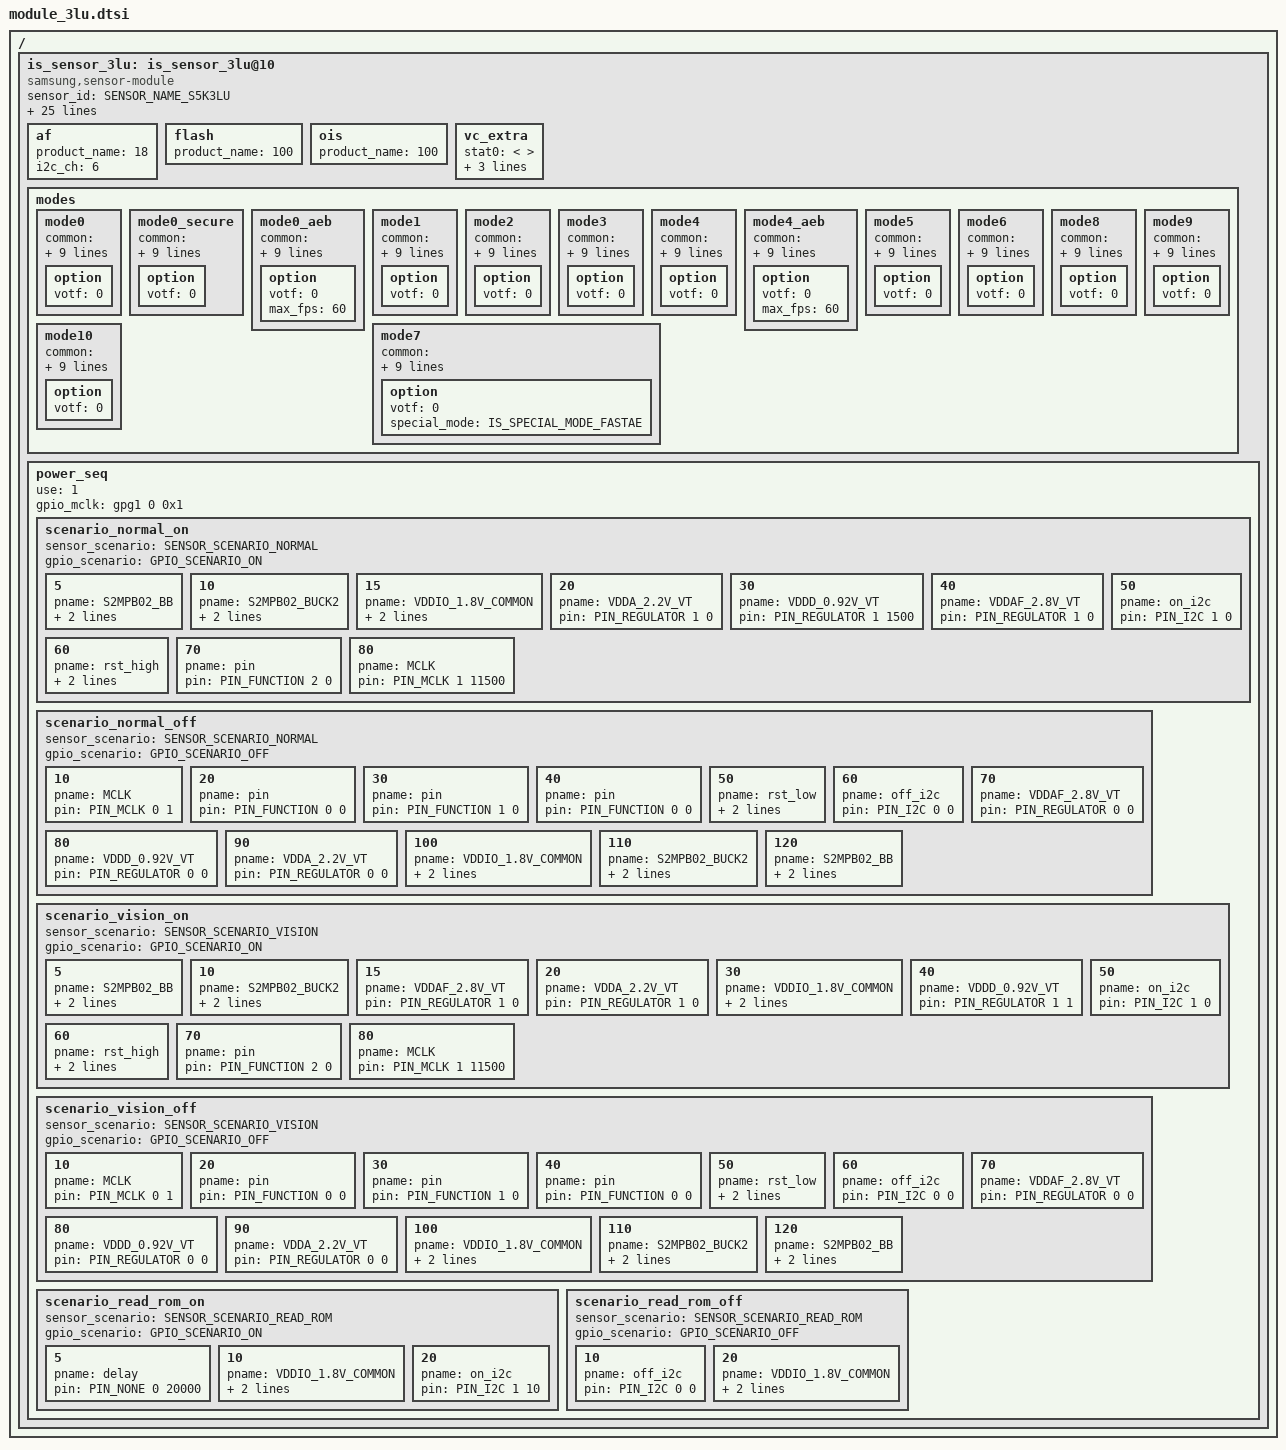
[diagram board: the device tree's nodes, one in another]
/*
 * SAMSUNG EXYNOSxxxx board camera device tree source
 *
 * Copyright (c) 2019 Samsung Electronics Co., Ltd.
 *		http://www.samsung.com
 *
 * This program is free software; you can redistribute it and/or modify
 * it under the terms of the GNU General Public License version 2 as
 * published by the Free Software Foundation.
 */

#include <dt-bindings/camera/exynos_is_dt.h>

/ {
	fragment@camera {
		target-path = "/";
		__overlay__ {
			is_sensor_3lu: is_sensor_3lu@10 {
				compatible = "samsung,sensor-module";

				/* common */
				sensor_id = <SENSOR_NAME_S5K3LU>;
				active_width = <4000>;
				active_height = <3000>;
				margin_left = <0>;
				margin_right = <0>;
				margin_top = <0>;
				margin_bottom = <0>;
				max_framerate = <240>;
				bitwidth = <10>;
				use_retention_mode = <SENSOR_RETENTION_UNSUPPORTED>;
				sensor_maker = "SLSI";
				sensor_name = "S5K3LU";
				setfile_name = "setfile_3lu.bin";

				status = "okay";

				/* board */
				pinctrl-names = "pin0", "pin1", "pin2", "release";
				pinctrl-0 = <>;
				pinctrl-1 = <&sensor_mclk0_out>;
				pinctrl-2 = <&sensor_mclk0_fn>;
				pinctrl-3 = <>;

				position = <1>;	/* Rear:0. Front:1. Rear_sub:2. Secure:3. */
				id = <1>; /* is_sensor id */
				mclk_ch = <0>;
				mclk_freq = <19200>;
				sensor_i2c_ch = <5>; /* SENSOR_CONTROL_I2C5 */

				/* vendor */
				rom_type = <2>; /* ROM_TYPE_EEPROM */
				rom_id = <1>;
				rom_cal_index = <0>;

				/* peri*/
				af {
					product_name = <18>; /* ACTUATOR_NAME_AK737X */
					i2c_ch = <6>; /* SENSOR_CONTROL_I2C6 */
				};

				flash {
					product_name = <100>; /* NOTHING */
				};

				ois {
					product_name = <100>; /* NOTHING */
				};

				vc_extra {
					/* ex) statX = <stat_type, sensor_mode, max_width, max_height, max_element> */
					stat0 = </* not available */>;									/* VC_BUF_DATA_TYPE_SENSOR_STAT1 */
					stat1 = </*VC_STAT_TYPE_PDP_4_1_PDAF_STAT0*/ 1200 /*VC_SENSOR_MODE_2PD_MODE3*/ 102 4000 750 2>;	/* VC_BUF_DATA_TYPE_GENERAL_STAT1 */
					stat2 = </* not available */>;									/* VC_BUF_DATA_TYPE_SENSOR_STAT2 */
					stat3 = </*VC_STAT_TYPE_PDP_4_1_PDAF_STAT1*/ 1201 /*VC_SENSOR_MODE_2PD_MODE3*/ 102 4000 750 2>;	/* VC_BUF_DATA_TYPE_GENERAL_STAT2 */
				};

				/* sensor modes */
				/*
					SENSOR_3LU_4000X3000_60FPS_10BIT = 0, // A-01-A
					SENSOR_3LU_3392X2544_60FPS_10BIT = 1, // A-01-B
					SENSOR_3LU_3392X1908_60FPS_10BIT = 2, // A-01-C
					SENSOR_3LU_4000X3000_30FPS_ADC = 3, // A-04
					SENSOR_3LU_4000X2252_60FPS_10BIT = 4, // A-09-B
					SENSOR_3LU_4000X2252_60FPS_ADC = 5, // A-12
					SENSOR_3LU_2000X1124_120FPS_10BIT = 6, // B-01
					SENSOR_3LU_2000X1500_120FPS_FAST_AE = 7, // C-02
					SENSOR_3LU_2000X1500_30FPS_10BIT = 8, // C-04-A
					SENSOR_3LU_1696X1272_30FPS_10BIT = 9, // C-04-B
					SENSOR_3LU_1696X954_30FPS_10BIT = 10, // C-04-C
					SENSOR_3LU_4000X3000_30FPS_DSG, // A-03
					SENSOR_3LU_4000X3000_30FPS_12BIT_LN2, // A-06
					SENSOR_3LU_4000X3000_60FPS_AEB, // A-05
					SENSOR_3LU_4000X3000_15FPS_10BIT_LN4, // A-07
					SENSOR_3LU_4000X2252_30FPS_DSG, // A-11-A
					SENSOR_3LU_4000X2252_30FPS_12BIT_LN2, // A-14-A
					SENSOR_3LU_4000X2252_15FPS_10BIT_LN4, // A-16
					SENSOR_3LU_4000X2252_30FPS_10BIT_LN2, // A-18
					SENSOR_3LU_4000X2252_60FPS_AEB, // A-19
				*/
				modes {
					/* common = <width, height, fps, settle, mode, lane, speed, interleave, lrte, pd_mode> */
					/* vcX = <map, hwformat, width, height, hwformat, type, width, height> */
					mode0 { /* SENSOR_3LU_4000X3000_60FPS_10BIT = 0 */ /* A-01-A */
						common = <4000 3000 60 0 0 CSI_DATA_LANES_3 1862 CSI_MODE_VC_DT LRTE_ENABLE PD_MOD3>;
						vc0 = </* in */ 0 HW_FORMAT_RAW10 DATA_IMG 4000 3000	/* out */ HW_FORMAT_RAW10 VC_NOTHING 4000 3000>;
						vc1 = </* in */ 2 HW_FORMAT_UNKNOWN DATA_NONE 0 0		/* out */ HW_FORMAT_UNKNOWN VC_NOTHING 0 0>;
						vc2 = </* in */ 1 HW_FORMAT_RAW10_POTF DATA_HPD 4000 750	/* out */ HW_FORMAT_RAW10_POTF VC_TAILPDAF 4000 750>;
						vc3 = </* in */ 3 HW_FORMAT_UNKNOWN DATA_NONE 0 0		/* out */ HW_FORMAT_UNKNOWN VC_NOTHING 0 0>;
						option { votf = <0>; };
					};
					mode0_secure { /* A-17 */
						common = <4000 3000 60 0 0 CSI_DATA_LANES_3 1862 CSI_MODE_VC_DT LRTE_ENABLE PD_NONE EX_PDSTAT_OFF>;
						vc0 = </* in */ 0 HW_FORMAT_RAW10 DATA_IMG 4000 3000	/* out */ HW_FORMAT_RAW10 VC_NOTHING 2000 1500>;
						vc1 = </* in */ 2 HW_FORMAT_UNKNOWN DATA_NONE 0 0		/* out */ HW_FORMAT_UNKNOWN VC_NOTHING 0 0>;
						vc2 = </* in */ 1 HW_FORMAT_RAW10_POTF DATA_HPD 4000 750	/* out */ HW_FORMAT_RAW10 VC_NOTHING 0 0>;
						vc3 = </* in */ 3 HW_FORMAT_UNKNOWN DATA_NONE 0 0		/* out */ HW_FORMAT_UNKNOWN VC_NOTHING 0 0>;
						option { votf = <0>; };
					};
					mode0_aeb { /* SENSOR_3LU_4000X3000_60FPS_10BIT = 0 */ /* A-01-A */ /* AEB */
						common = <4000 3000 60 0 0 CSI_DATA_LANES_3 1862 CSI_MODE_VC_DT LRTE_ENABLE PD_MOD3 EX_AEB>;
						vc0 = </* in */ 0 HW_FORMAT_RAW10 DATA_IMG 4000 3000	/* out */ HW_FORMAT_RAW10 VC_NOTHING 4000 3000>;
						vc1 = </* in */ 2 HW_FORMAT_RAW10 DATA_IMG 4000 3000	/* out */ HW_FORMAT_RAW10 VC_NOTHING 4000 3000>;
						vc2 = </* in */ 1 HW_FORMAT_RAW10_POTF DATA_HPD 4000 750	/* out */ HW_FORMAT_RAW10_POTF VC_TAILPDAF 4000 750>;
						vc3 = </* in */ 3 HW_FORMAT_RAW10_POTF DATA_HPD 4000 750	/* out */ HW_FORMAT_UNKNOWN VC_NOTHING 0 0>;
						option { votf = <0>; max_fps = <60>; };
					};
					mode1 { /* SENSOR_3LU_3392X2544_60FPS_10BIT = 1 */ /* A-01-B */
						common = <3392 2544 60 0 1 CSI_DATA_LANES_3 1862 CSI_MODE_VC_DT LRTE_ENABLE PD_MOD3>;
						vc0 = </* in */ 0 HW_FORMAT_RAW10 DATA_IMG 3392 2544	/* out */ HW_FORMAT_RAW10 VC_NOTHING 3392 2544>;
						vc1 = </* in */ 2 HW_FORMAT_UNKNOWN DATA_NONE 0 0		/* out */ HW_FORMAT_UNKNOWN VC_NOTHING 0 0>;
						vc2 = </* in */ 1 HW_FORMAT_RAW10_POTF DATA_HPD 3392 636	/* out */ HW_FORMAT_RAW10_POTF VC_TAILPDAF 3392 636>;
						vc3 = </* in */ 3 HW_FORMAT_UNKNOWN DATA_NONE 0 0		/* out */ HW_FORMAT_UNKNOWN VC_NOTHING 0 0>;
						option { votf = <0>; };
					};
					mode2 { /* SENSOR_3LU_3392X1908_60FPS_10BIT = 2 */ /* A-01-C */
						common = <3392 1908 60 0 2 CSI_DATA_LANES_3 1862 CSI_MODE_VC_DT LRTE_ENABLE PD_MOD3>;
						vc0 = </* in */ 0 HW_FORMAT_RAW10 DATA_IMG 3392 1908	/* out */ HW_FORMAT_RAW10 VC_NOTHING 3392 1908>;
						vc1 = </* in */ 2 HW_FORMAT_UNKNOWN DATA_NONE 0 0		/* out */ HW_FORMAT_UNKNOWN VC_NOTHING 0 0>;
						vc2 = </* in */ 1 HW_FORMAT_RAW10_POTF DATA_HPD 3392 476	/* out */ HW_FORMAT_RAW10_POTF VC_TAILPDAF 3392 476>;
						vc3 = </* in */ 3 HW_FORMAT_UNKNOWN DATA_NONE 0 0		/* out */ HW_FORMAT_UNKNOWN VC_NOTHING 0 0>;
						option { votf = <0>; };
					};
					mode3 { /* SENSOR_3LU_4000X3000_30FPS_ADC = 3 */ /* A-04 */
						common = <4000 3000 30 0 3 CSI_DATA_LANES_3 1862 CSI_MODE_VC_DT LRTE_ENABLE PD_MOD3>;
						vc0 = </* in */ 0 HW_FORMAT_RAW12 DATA_IMG 4000 3000	/* out */ HW_FORMAT_RAW12 VC_NOTHING 4000 3000>;
						vc1 = </* in */ 2 HW_FORMAT_UNKNOWN DATA_NONE 0 0		/* out */ HW_FORMAT_UNKNOWN VC_NOTHING 0 0>;
						vc2 = </* in */ 1 HW_FORMAT_RAW10_POTF DATA_HPD 4000 750	/* out */ HW_FORMAT_RAW10_POTF VC_TAILPDAF 4000 750>;
						vc3 = </* in */ 3 HW_FORMAT_UNKNOWN DATA_NONE 0 0		/* out */ HW_FORMAT_UNKNOWN VC_NOTHING 0 0>;
						option { votf = <0>; };
					};
					mode4 { /* SENSOR_3LU_4000X2252_60FPS_10BIT = 4 */ /* A-09-B */
						common = <4000 2252 60 0 4 CSI_DATA_LANES_3 1862 CSI_MODE_VC_DT LRTE_ENABLE PD_MOD3>;
						vc0 = </* in */ 0 HW_FORMAT_RAW10 DATA_IMG 4000 2252	/* out */ HW_FORMAT_RAW10 VC_NOTHING 4000 2252>;
						vc1 = </* in */ 2 HW_FORMAT_UNKNOWN DATA_NONE 0 0		/* out */ HW_FORMAT_UNKNOWN VC_NOTHING 0 0>;
						vc2 = </* in */ 1 HW_FORMAT_RAW10_POTF DATA_HPD 4000 562	/* out */ HW_FORMAT_RAW10_POTF VC_TAILPDAF 4000 562>;
						vc3 = </* in */ 3 HW_FORMAT_UNKNOWN DATA_NONE 0 0		/* out */ HW_FORMAT_UNKNOWN VC_NOTHING 0 0>;
						option { votf = <0>; };
					};
					mode4_aeb { /* SENSOR_3LU_4000X2252_60FPS_10BIT = 4 */ /* A-09 */ /* AEB */
						common = <4000 2252 60 0 4 CSI_DATA_LANES_3 1862 CSI_MODE_VC_DT LRTE_ENABLE PD_MOD3 EX_AEB>;
						vc0 = </* in */ 0 HW_FORMAT_RAW10 DATA_IMG 4000 2252	/* out */ HW_FORMAT_RAW10 VC_NOTHING 4000 2252>;
						vc1 = </* in */ 2 HW_FORMAT_RAW10 DATA_IMG 4000 2252	/* out */ HW_FORMAT_RAW10 VC_NOTHING 4000 2252>;
						vc2 = </* in */ 1 HW_FORMAT_RAW10_POTF DATA_HPD 4000 562	/* out */ HW_FORMAT_RAW10_POTF VC_TAILPDAF 4000 562>;
						vc3 = </* in */ 3 HW_FORMAT_RAW10_POTF DATA_HPD 4000 562	/* out */ HW_FORMAT_UNKNOWN VC_NOTHING 0 0>;
						option { votf = <0>; max_fps = <60>; };
					};
					mode5 { /* SENSOR_3LU_4000X2252_60FPS_ADC = 5 */ /* A-12 */
						common = <4000 2252 60 0 5 CSI_DATA_LANES_3 1862 CSI_MODE_VC_DT LRTE_ENABLE PD_MOD3>;
						vc0 = </* in */ 0 HW_FORMAT_RAW12 DATA_IMG 4000 2252	/* out */ HW_FORMAT_RAW12 VC_NOTHING 4000 2252>;
						vc1 = </* in */ 2 HW_FORMAT_UNKNOWN DATA_NONE 0 0		/* out */ HW_FORMAT_UNKNOWN VC_NOTHING 0 0>;
						vc2 = </* in */ 1 HW_FORMAT_RAW10_POTF DATA_HPD 4000 562	/* out */ HW_FORMAT_RAW10_POTF VC_TAILPDAF 4000 562>;
						vc3 = </* in */ 3 HW_FORMAT_UNKNOWN DATA_NONE 0 0		/* out */ HW_FORMAT_UNKNOWN VC_NOTHING 0 0>;
						option { votf = <0>; };
					};
					mode6 { /* SENSOR_3LU_2000X1124_120FPS_10BIT = 6 */ /* B-01 */
						common = <2000 1124 120 0 6 CSI_DATA_LANES_3 1196 CSI_MODE_VC_DT LRTE_ENABLE PD_MOD3>;
						vc0 = </* in */ 0 HW_FORMAT_RAW10 DATA_IMG 2000 1124	/* out */ HW_FORMAT_RAW10 VC_NOTHING 2000 1124>;
						vc1 = </* in */ 2 HW_FORMAT_UNKNOWN DATA_NONE 0 0		/* out */ HW_FORMAT_UNKNOWN VC_NOTHING 0 0>;
						vc2 = </* in */ 1 HW_FORMAT_RAW10_POTF DATA_HPD 2000 280	/* out */ HW_FORMAT_RAW10_POTF VC_TAILPDAF 2000 280>;
						vc3 = </* in */ 3 HW_FORMAT_UNKNOWN DATA_NONE 0 0		/* out */ HW_FORMAT_UNKNOWN VC_NOTHING 0 0>;
						option { votf = <0>; };
					};
					mode7 { /* SENSOR_3LU_2000X1500_120FPS_FAST_AE = 7 */ /* C-02 */
						common = <2000 1500 120 0 7 CSI_DATA_LANES_3 1196 CSI_MODE_VC_DT LRTE_ENABLE PD_NONE>;
						vc0 = </* in */ 0 HW_FORMAT_RAW10 DATA_IMG 2000 1500	/* out */ HW_FORMAT_RAW10 VC_NOTHING 2000 1500>;
						vc1 = </* in */ 1 HW_FORMAT_UNKNOWN DATA_NONE 0 0		/* out */ HW_FORMAT_UNKNOWN VC_NOTHING 0 0>;
						vc2 = </* in */ 2 HW_FORMAT_UNKNOWN DATA_NONE 0 0		/* out */ HW_FORMAT_UNKNOWN VC_NOTHING 0 0>;
						vc3 = </* in */ 3 HW_FORMAT_UNKNOWN DATA_NONE 0 0		/* out */ HW_FORMAT_UNKNOWN VC_NOTHING 0 0>;
						option { votf = <0>; special_mode = <IS_SPECIAL_MODE_FASTAE>; };
					};
					mode8 { /* SENSOR_3LU_2000X1500_30FPS_10BIT = 8 */ /* C-04-A */
						common = <2000 1500 30 0 8 CSI_DATA_LANES_3 1196 CSI_MODE_VC_DT LRTE_ENABLE PD_MOD3>;
						vc0 = </* in */ 0 HW_FORMAT_RAW10 DATA_IMG 2000 1500	/* out */ HW_FORMAT_RAW10 VC_NOTHING 2000 1500>;
						vc1 = </* in */ 2 HW_FORMAT_UNKNOWN DATA_NONE 0 0		/* out */ HW_FORMAT_UNKNOWN VC_NOTHING 0 0>;
						vc2 = </* in */ 1 HW_FORMAT_RAW10_POTF DATA_HPD 2000 374	/* out */ HW_FORMAT_RAW10_POTF VC_TAILPDAF 2000 374>;
						vc3 = </* in */ 3 HW_FORMAT_UNKNOWN DATA_NONE 0 0		/* out */ HW_FORMAT_UNKNOWN VC_NOTHING 0 0>;
						option { votf = <0>; };
					};
					mode9 { /* SENSOR_3LU_1696X1272_30FPS_10BIT = 9 */ /* C-04-B */
						common = <1696 1272 30 0 9 CSI_DATA_LANES_3 1196 CSI_MODE_VC_DT LRTE_ENABLE PD_MOD3>;
						vc0 = </* in */ 0 HW_FORMAT_RAW10 DATA_IMG 1696 1272	/* out */ HW_FORMAT_RAW10 VC_NOTHING 1696 1272>;
						vc1 = </* in */ 2 HW_FORMAT_UNKNOWN DATA_NONE 0 0		/* out */ HW_FORMAT_UNKNOWN VC_NOTHING 0 0>;
						vc2 = </* in */ 1 HW_FORMAT_RAW10_POTF DATA_HPD 1696 318	/* out */ HW_FORMAT_RAW10_POTF VC_TAILPDAF 1696 318>;
						vc3 = </* in */ 3 HW_FORMAT_UNKNOWN DATA_NONE 0 0		/* out */ HW_FORMAT_UNKNOWN VC_NOTHING 0 0>;
						option { votf = <0>; };
					};
					mode10 { /* SENSOR_3LU_1696X954_30FPS_10BIT = 10 */ /* C-04-C */
						common = <1696 954 30 0 10 CSI_DATA_LANES_3 1196 CSI_MODE_VC_DT LRTE_ENABLE PD_MOD3>;
						vc0 = </* in */ 0 HW_FORMAT_RAW10 DATA_IMG 1696 954	/* out */ HW_FORMAT_RAW10 VC_NOTHING 1696 954>;
						vc1 = </* in */ 2 HW_FORMAT_UNKNOWN DATA_NONE 0 0		/* out */ HW_FORMAT_UNKNOWN VC_NOTHING 0 0>;
						vc2 = </* in */ 1 HW_FORMAT_RAW10_POTF DATA_HPD 1696 238	/* out */ HW_FORMAT_RAW10_POTF VC_TAILPDAF 1696 238>;
						vc3 = </* in */ 3 HW_FORMAT_UNKNOWN DATA_NONE 0 0		/* out */ HW_FORMAT_UNKNOWN VC_NOTHING 0 0>;
						option { votf = <0>; };
					};
				};

				power_seq {
					use = <1>;
					gpio_mclk = <&gpg1 0 0x1>;
					scenario_normal_on {
						sensor_scenario = <SENSOR_SCENARIO_NORMAL>;
						gpio_scenario = <GPIO_SCENARIO_ON>;

						/* A start node number should be over the 10 for reserved number 0~9. */
						/* pname = "name"; pin = <act value delay voltage>; gpio = <gpx# # 0x1>; */
						5 { pname = "S2MPB02_BB"; pin = <PIN_REGULATOR 1 0>; share = <SRT_ACQUIRE SHARED_PIN2 1>; };
						10 { pname = "S2MPB02_BUCK2"; pin = <PIN_REGULATOR 1 0>; share = <SRT_ACQUIRE SHARED_PIN1 1>; };
						15 { pname = "VDDIO_1.8V_COMMON"; pin = <PIN_REGULATOR 1 1>; share = <SRT_ACQUIRE SHARED_PIN0 1>; };
						20 { pname = "VDDA_2.2V_VT"; pin = <PIN_REGULATOR 1 0>; };
						30 { pname = "VDDD_0.92V_VT"; pin = <PIN_REGULATOR 1 1500>; };
						40 { pname = "VDDAF_2.8V_VT"; pin = <PIN_REGULATOR 1 0>; };
						50 { pname = "on_i2c"; pin = <PIN_I2C 1 0>; };
						60 { pname = "rst_high"; pin = <PIN_OUTPUT 1 0>; gpio = <&gpp9 1 0x1>; };
						70 { pname = "pin"; pin = <PIN_FUNCTION 2 0>; };
						80 { pname = "MCLK"; pin = <PIN_MCLK 1 11500>; };
					};

					scenario_normal_off {
						sensor_scenario = <SENSOR_SCENARIO_NORMAL>;
						gpio_scenario = <GPIO_SCENARIO_OFF>;

						/* A start node number should be over the 10 for reserved number 0~9. */
						/* pname = "name"; pin = <act value delay voltage>; gpio = <gpx# # 0x1>; */
						10 { pname = "MCLK"; pin = <PIN_MCLK 0 1>; };
						20 { pname = "pin"; pin = <PIN_FUNCTION 0 0>; };
						30 { pname = "pin"; pin = <PIN_FUNCTION 1 0>; };
						40 { pname = "pin"; pin = <PIN_FUNCTION 0 0>; };
						50 { pname = "rst_low"; pin = <PIN_OUTPUT 0 0>; gpio = <&gpp9 1 0x1>; };
						60 { pname = "off_i2c"; pin = <PIN_I2C 0 0>; };
						70 { pname = "VDDAF_2.8V_VT"; pin = <PIN_REGULATOR 0 0>; };
						80 { pname = "VDDD_0.92V_VT"; pin = <PIN_REGULATOR 0 0>; };
						90 { pname = "VDDA_2.2V_VT"; pin = <PIN_REGULATOR 0 0>; };
						100 { pname = "VDDIO_1.8V_COMMON"; pin = <PIN_REGULATOR 0 0>; share = <SRT_RELEASE SHARED_PIN0 0>; };
						110 { pname = "S2MPB02_BUCK2"; pin = <PIN_REGULATOR 0 0>; share = <SRT_RELEASE SHARED_PIN1 0>; };
						120 { pname = "S2MPB02_BB"; pin = <PIN_REGULATOR 0 0>; share = <SRT_RELEASE SHARED_PIN2 0>; };
					};

					scenario_vision_on {
						sensor_scenario = <SENSOR_SCENARIO_VISION>;
						gpio_scenario = <GPIO_SCENARIO_ON>;

						/* A start node number should be over the 10 for reserved number 0~9. */
						/* pname = "name"; pin = <act value delay voltage>; gpio = <gpx# # 0x1>; */
						5 { pname = "S2MPB02_BB"; pin = <PIN_REGULATOR 1 0>; share = <SRT_ACQUIRE SHARED_PIN2 1>; };
						10 { pname = "S2MPB02_BUCK2"; pin = <PIN_REGULATOR 1 0>; share = <SRT_ACQUIRE SHARED_PIN1 1>; };
						15 { pname = "VDDAF_2.8V_VT"; pin = <PIN_REGULATOR 1 0>; };
						20 { pname = "VDDA_2.2V_VT"; pin = <PIN_REGULATOR 1 0>; };
						30 { pname = "VDDIO_1.8V_COMMON"; pin = <PIN_REGULATOR 1 0>; share = <SRT_ACQUIRE SHARED_PIN0 1>; };
						40 { pname = "VDDD_0.92V_VT"; pin = <PIN_REGULATOR 1 1>; };
						50 { pname = "on_i2c"; pin = <PIN_I2C 1 0>; };
						60 { pname = "rst_high"; pin = <PIN_OUTPUT 1 0>; gpio = <&gpp9 1 0x1>; };
						70 { pname = "pin"; pin = <PIN_FUNCTION 2 0>; };
						80 { pname = "MCLK"; pin = <PIN_MCLK 1 11500>; };
					};

					scenario_vision_off {
						sensor_scenario = <SENSOR_SCENARIO_VISION>;
						gpio_scenario = <GPIO_SCENARIO_OFF>;

						/* A start node number should be over the 10 for reserved number 0~9. */
						/* pname = "name"; pin = <act value delay voltage>; gpio = <gpx# # 0x1>; */
						10 { pname = "MCLK"; pin = <PIN_MCLK 0 1>; };
						20 { pname = "pin"; pin = <PIN_FUNCTION 0 0>; };
						30 { pname = "pin"; pin = <PIN_FUNCTION 1 0>; };
						40 { pname = "pin"; pin = <PIN_FUNCTION 0 0>; };
						50 { pname = "rst_low"; pin = <PIN_OUTPUT 0 0>; gpio = <&gpp9 1 0x1>; };
						60 { pname = "off_i2c"; pin = <PIN_I2C 0 0>; };
						70 { pname = "VDDAF_2.8V_VT"; pin = <PIN_REGULATOR 0 0>; };
						80 { pname = "VDDD_0.92V_VT"; pin = <PIN_REGULATOR 0 0>; };
						90 { pname = "VDDA_2.2V_VT"; pin = <PIN_REGULATOR 0 0>; };
						100 { pname = "VDDIO_1.8V_COMMON"; pin = <PIN_REGULATOR 0 0>; share = <SRT_RELEASE SHARED_PIN0 0>; };
						110 { pname = "S2MPB02_BUCK2"; pin = <PIN_REGULATOR 0 0>; share = <SRT_RELEASE SHARED_PIN1 0>; };
						120 { pname = "S2MPB02_BB"; pin = <PIN_REGULATOR 0 0>; share = <SRT_RELEASE SHARED_PIN2 0>; };
					};

					scenario_read_rom_on {
						sensor_scenario = <SENSOR_SCENARIO_READ_ROM>;
						gpio_scenario = <GPIO_SCENARIO_ON>;

						/* A start node number should be over the 10 for reserved number 0~9. */
						/* pname = "name"; pin = <act value delay voltage>; gpio = <gpx# # 0x1>; */
						5 { pname = "delay"; pin = <PIN_NONE 0 20000>; };
						10 { pname = "VDDIO_1.8V_COMMON"; pin = <PIN_REGULATOR 1 5000>; share = <SRT_ACQUIRE SHARED_PIN0 1>; };
						20 { pname = "on_i2c"; pin = <PIN_I2C 1 10>; };
					};

					scenario_read_rom_off {
						sensor_scenario = <SENSOR_SCENARIO_READ_ROM>;
						gpio_scenario = <GPIO_SCENARIO_OFF>;

						/* A start node number should be over the 10 for reserved number 0~9. */
						/* pname = "name"; pin = <act value delay voltage>; gpio = <gpx# # 0x1>; */
						10 { pname = "off_i2c"; pin = <PIN_I2C 0 0>; };
						20 { pname = "VDDIO_1.8V_COMMON"; pin = <PIN_REGULATOR 0 0>; share = <SRT_RELEASE SHARED_PIN0 0>; };
					};
				};
			};
		}; /* end of __overlay__ */
	}; /* end of fragment */
}; /* end of root */
